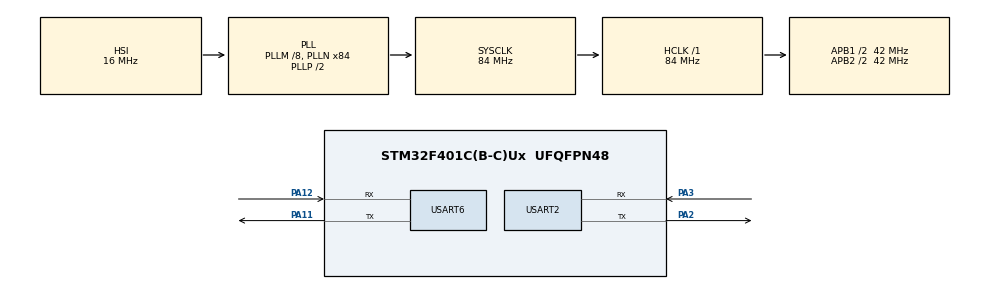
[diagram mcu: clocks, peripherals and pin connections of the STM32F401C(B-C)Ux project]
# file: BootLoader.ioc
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Mcu.Family=STM32F4
Mcu.Name=STM32F401C(B-C)Ux
Mcu.Package=UFQFPN48
NVIC.PriorityGroup=NVIC_PRIORITYGROUP_4
NVIC.TIM3_IRQn=true\:0\:0\:false\:false\:true\:true\:true\:true
PA11.Mode=Asynchronous
PA11.Signal=USART6_TX
PA12.Mode=Asynchronous
PA12.Signal=USART6_RX
PA13.Mode=Serial_Wire
PA13.Signal=SYS_JTMS-SWDIO
PA14.Mode=Serial_Wire
PA14.Signal=SYS_JTCK-SWCLK
PA2.Mode=Asynchronous
PA2.Signal=USART2_TX
PA3.Mode=Asynchronous
PA3.Signal=USART2_RX
ProjectManager.HeapSize=0x200
ProjectManager.StackSize=0x400
ProjectManager.TargetToolchain=STM32CubeIDE
RCC.48MHZClocksFreq_Value=42000000
RCC.AHBFreq_Value=84000000
RCC.APB1CLKDivider=RCC_HCLK_DIV2
RCC.APB1Freq_Value=42000000
RCC.APB1TimFreq_Value=84000000
RCC.APB2CLKDivider=RCC_HCLK_DIV2
RCC.APB2Freq_Value=42000000
RCC.APB2TimFreq_Value=84000000
RCC.CortexFreq_Value=84000000
RCC.HCLKFreq_Value=84000000
RCC.HSE_VALUE=16000000
RCC.HSI_VALUE=16000000
RCC.LSE_VALUE=32768
RCC.PLLM=8
RCC.PLLN=84
RCC.SYSCLKFreq_VALUE=84000000
RCC.SYSCLKSource=RCC_SYSCLKSOURCE_PLLCLK
RCC.VCOOutputFreq_Value=168000000
TIM3.Period=65535
TIM3.Prescaler=83
USART2.VirtualMode=VM_ASYNC
USART6.VirtualMode=VM_ASYNC
VP_CRC_VS_CRC.Mode=CRC_Activate
VP_TIM3_VS_ClockSourceINT.Mode=Internal
board=custom

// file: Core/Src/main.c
/* USER CODE BEGIN Header */
/**
 ******************************************************************************
 * @file           : main.c
 * @brief          : Main program body
 ******************************************************************************
 * @attention
 *
 * Copyright (c) 2024 STMicroelectronics.
 * All rights reserved.
 *
 * This software is licensed under terms that can be found in the LICENSE file
 * in the root directory of this software component.
 * If no LICENSE file comes with this software, it is provided AS-IS.
 *
 ******************************************************************************
 */
/* USER CODE END Header */
#include "main.h"
#include "crc.h"
#include "tim.h"
#include "usart.h"
#include "gpio.h"

/* USER CODE BEGIN Includes */
#include "STD_TYPES.h"
#include "Bootloader.h"

/* USER CODE END Includes */

/* USER CODE BEGIN PTD */
extern flag;
/* USER CODE END PTD */

void SystemClock_Config(void);

/* USER CODE BEGIN 0 */
//char Message_1[]="I Am Abdallah Essam\r\n";
//char Message_2[]="I Am ITI Student\r\n";
/* USER CODE END 0 */

int main(void)
{
  /* USER CODE BEGIN 1 */
	BL_Status Status = BL_NACK;

  /* USER CODE END 1 */

  /* MCU Configuration--------------------------------------------------------*/

  /* Reset of all peripherals, Initializes the Flash interface and the Systick. */
  HAL_Init();

  /* Configure the system clock */
  SystemClock_Config();

  /* USER CODE BEGIN SysInit */
	//RCC_AHB1ENR_GPIOAEN
  /* USER CODE END SysInit */

  /* Initialize all configured peripherals */
  MX_GPIO_Init();
  MX_CRC_Init();
  MX_USART2_UART_Init();
  MX_USART6_UART_Init();
  MX_TIM3_Init();
  /* USER CODE BEGIN 2 */
	// Start the timer with interrupt
	//HAL_TIM_Base_Start_IT(&htim3);
	//Recieve flag to syop timer if the host is sending data
	HAL_GPIO_WritePin(GPIOA, GPIO_PIN_1, GPIO_PIN_SET);
	//BL_Status status=BL_NACK;
#if(BL_DEBUG_ENABLE==DEBUG_INFO_ENABLE)
	BL_Print_Message("BootLoader Started\r\n");
#endif
	//HAL_GPIO_WritePin(GPIOD, GPIO_PIN_12, GPIO_PIN_SET);
	//Recieve_Status Recieve_flag =Recieve_NOK;
	//Status=BL_UART_Fetch_Host_Command();
	//HAL_TIM_Base_Start_IT(&htim3);
	//Recieve_Status Recieve_flag = Recieve_NOK;

  /* USER CODE END 2 */

  /* Infinite loop */
  /* USER CODE BEGIN WHILE */
	HAL_TIM_Base_Start_IT(&htim3);
	//HAL_TIM_Base_Stop_IT(&htim3);
	while (1)
	{
		Status=BL_UART_Fetch_Host_Command();
		//		if(BL_OK ==Status)
		//		{
		//			HAL_TIM_Base_Start_IT(&htim3);
		//			Recieve_flag =Recieve_OK;
		//		}
		//		else
		//		{
		//			Recieve_flag =Recieve_NOK;
		//		}
		//		if (1==flag && Recieve_flag ==Recieve_NOK)
		//		{
		//			Bootloader_Jump_To_User_App();
		//		}b

		if(BL_OK ==Status)
		{
			HAL_TIM_Base_Start_IT(&htim3);

		}
		if (1==flag)
		{
			Bootloader_Jump_To_User_App();
		}
	//	Bootloader_Jump_To_User_App();

		/*if(Status==BL_OK)
		{
			HAL_TIM_Base_Start_IT(&htim3);
		}*/
    /* USER CODE END WHILE */

	}
}

void SystemClock_Config(void)
{
  RCC_OscInitTypeDef RCC_OscInitStruct = {0};
  RCC_ClkInitTypeDef RCC_ClkInitStruct = {0};

  /** Configure the main internal regulator output voltage
  */
  __HAL_RCC_PWR_CLK_ENABLE();
  __HAL_PWR_VOLTAGESCALING_CONFIG(PWR_REGULATOR_VOLTAGE_SCALE2);

  /** Initializes the RCC Oscillators according to the specified parameters
  * in the RCC_OscInitTypeDef structure.
  */
  RCC_OscInitStruct.OscillatorType = RCC_OSCILLATORTYPE_HSI;
  RCC_OscInitStruct.HSIState = RCC_HSI_ON;
  RCC_OscInitStruct.HSICalibrationValue = RCC_HSICALIBRATION_DEFAULT;
  RCC_OscInitStruct.PLL.PLLState = RCC_PLL_ON;
  RCC_OscInitStruct.PLL.PLLSource = RCC_PLLSOURCE_HSI;
  RCC_OscInitStruct.PLL.PLLM = 8;
  RCC_OscInitStruct.PLL.PLLN = 84;
  RCC_OscInitStruct.PLL.PLLP = RCC_PLLP_DIV2;
  RCC_OscInitStruct.PLL.PLLQ = 4;
  if (HAL_RCC_OscConfig(&RCC_OscInitStruct) != HAL_OK)
  {
    Error_Handler();
  }

  /** Initializes the CPU, AHB and APB buses clocks
  */
  RCC_ClkInitStruct.ClockType = RCC_CLOCKTYPE_HCLK|RCC_CLOCKTYPE_SYSCLK
                              |RCC_CLOCKTYPE_PCLK1|RCC_CLOCKTYPE_PCLK2;
  RCC_ClkInitStruct.SYSCLKSource = RCC_SYSCLKSOURCE_PLLCLK;
  RCC_ClkInitStruct.AHBCLKDivider = RCC_SYSCLK_DIV1;
  RCC_ClkInitStruct.APB1CLKDivider = RCC_HCLK_DIV2;
  RCC_ClkInitStruct.APB2CLKDivider = RCC_HCLK_DIV2;

  if (HAL_RCC_ClockConfig(&RCC_ClkInitStruct, FLASH_LATENCY_2) != HAL_OK)
  {
    Error_Handler();
  }
}

void Error_Handler(void)
{
	__disable_irq();
	while (1)
	{
	}
}
